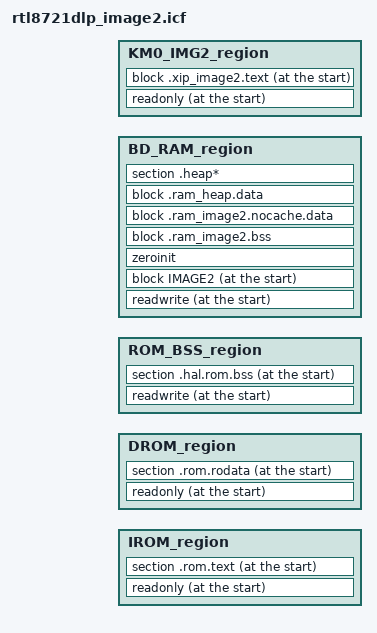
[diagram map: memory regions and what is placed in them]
/*###ICF### Section handled by ICF editor, don't touch! ****/
/*-Editor annotation file-*/
/* IcfEditorFile="$TOOLKIT_DIR$\config\ide\IcfEditor\cortex_v1_0.xml" */
/*-Specials-*/

include "rtl8721dlp_rom_symbol.icf";
include "rtl8721d_memory_layout_is.icf";

/*-Sizes-*/
/*define symbol __ICFEDIT_size_cstack__   = 0x400;*/
/*define symbol __ICFEDIT_size_heap__     = 0x800;*/
/**** End of ICF editor section. ###ICF###*/

define memory mem with size = 4G;
define region IROM_region   = mem:[from __ICFEDIT_region_LS_IROM_start__   to __ICFEDIT_region_LS_IROM_end__];
define region DROM_region   = mem:[from __ICFEDIT_region_LS_DROM_start__   to __ICFEDIT_region_LS_DROM_end__];
define region ROM_BSS_region   = mem:[from __ICFEDIT_region_LS_ROMBSS_RAM_start__   to __ICFEDIT_region_LS_ROMBSS_RAM_end__];
define region BOOT_RAM_region   = mem:[from __ICFEDIT_region_LS_BOOTLOADER_RAM_start__   to __ICFEDIT_region_LS_BOOTLOADER_RAM_end__];
define region BD_RAM_region   = mem:[from __ICFEDIT_region_LS_BD_RAM_start__   to __ICFEDIT_region_LS_BD_RAM_end__];
define region KM0_BOOT_region   = mem:[from __ICFEDIT_region_LS_FLASH_BOOT_start__   to __ICFEDIT_region_LS_FLASH_BOOT_end__];
define region KM0_IMG2_region   = mem:[from __ICFEDIT_region_LS_FLASH_IMG2_start__   to __ICFEDIT_region_LS_FLASH_IMG2_end__];
define region RETENTION_RAM_region   =mem:[from __ICFEDIT_region_RETENTION_RAM_start__   to __ICFEDIT_region_RETENTION_RAM_end__];

/*define block CSTACK    with alignment = 8, size = __ICFEDIT_size_cstack__   { };*/
/*define block HEAP      with alignment = 8, size = __ICFEDIT_size_heap__     { };*/

//initialize by copy { readwrite };
//initialize by copy with packing = none { section __DLIB_PERTHREAD }; // Required in a multi-threaded application

//do not initialize  { section * };
do not initialize { readwrite };

/****************************************
 * ROM Section config                   *
 ****************************************/
keep { section .rom.text };
place at start of IROM_region   { readonly, section .rom.text };

keep { section .rom.rodata };
place at start of DROM_region   { readonly, section .rom.rodata };

/****************************************
 * ROM BSS Section config                *
 ****************************************/
keep { section .hal.rom.bss };
place at start of ROM_BSS_region  { readwrite, section .hal.rom.bss };

/****************************************
 * BD RAM Section config                *
 ****************************************/
keep { section .image2.entry.data* };
keep { section .image2.validate.rodata* };
define block .ram_image2.entry with fixed order{section .image2.entry.data*,
						section .image2.validate.rodata*,
						};

define block .ram_image2.text with fixed order{section .image2.ram.text*};

define block SHT$$PREINIT_ARRAY { preinit_array };
define block SHT$$INIT_ARRAY { init_array };
define block CPP_INIT with fixed order { block SHT$$PREINIT_ARRAY,
					block SHT$$INIT_ARRAY };
define block .ram_image2.data with fixed order{ section .data*,
						section DATA, 
						section .iar.init_table,
						section __DLIB_PERTHREAD,
                                                block CPP_INIT,
						};

define block IMAGE2 with fixed order { block .ram_image2.entry,
                                       block .ram_image2.text,
                                       block .ram_image2.data,
};

define block .ram_image2.bss with fixed order{section .bss*,
                                              section .FW.ram.bss*,
					      section COMMON,
					     };


define block .ram_image2.nocache.data with alignment = 32 {section .bdsram.data*};


define block .ram_heap.data with fixed order { section .bfsram.data*,
                                               section .heap.stdlib*,
                                             };

place at start of BD_RAM_region   { readwrite, 
                                    block IMAGE2,
                                  };
                                  
place in BD_RAM_region {zeroinit,
                                    block .ram_image2.bss,
                                    block .ram_image2.nocache.data,
                                    block .ram_heap.data,
                                    section .heap*};

/****************************************
 * XIP Image2 Section config                *
 ****************************************/
keep { section .cmd.table.data* };
define block .xip_image2.text with fixed order{ section .img2_custom_signature*,
                                                section .text*,
                                                section .rodata*,
                                                section .cmd.table.data*,
                                                section .debug_trace,
						section CODE,
						section Veneer,
                                              };

place at start of KM0_IMG2_region   {  readonly,
					 block .xip_image2.text };


define exported symbol __retention_entry_func__= start(RETENTION_RAM_region);


